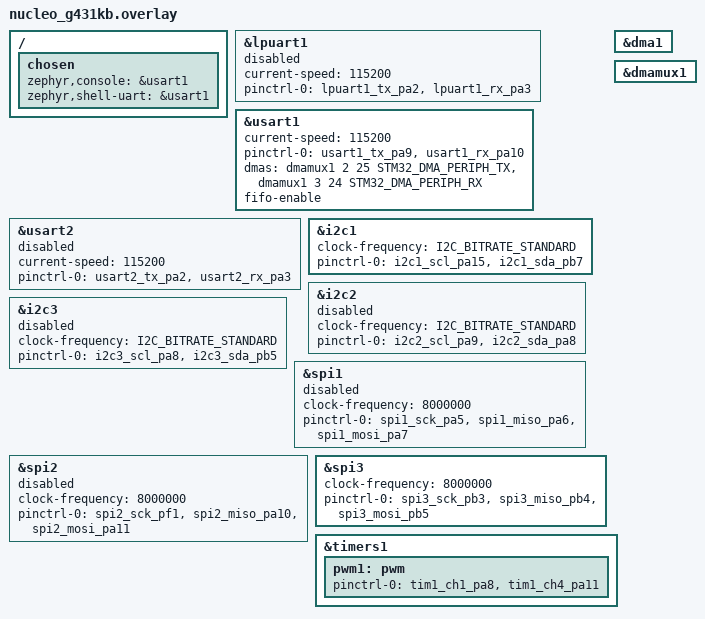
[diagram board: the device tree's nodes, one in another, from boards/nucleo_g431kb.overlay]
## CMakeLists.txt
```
# Copyright (c) 2024 Takayuki Goto <tkg.develop@gmail.com>
# SPDX-License-Identifier: Apache-2.0

cmake_minimum_required(VERSION 3.13.1)

list(APPEND DTS_ROOT ${CMAKE_CURRENT_SOURCE_DIR})

## Switch by Target
if (BOARD STREQUAL "bbc_microbit")
  set(CONF_FILE ${CMAKE_CURRENT_SOURCE_DIR}/boards/bbc/microbit/prj.conf)
elseif (BOARD STREQUAL "bbc_microbit_v2")
  set(CONF_FILE ${CMAKE_CURRENT_SOURCE_DIR}/boards/bbc/microbit_v2/prj.conf)
elseif (BOARD STREQUAL "nucleo_g431kb")
  set(CONF_FILE ${CMAKE_CURRENT_SOURCE_DIR}/boards/st/nucleo_g431kb/prj.conf)
elseif (BOARD STREQUAL "nucleo_f030r8")
  set(CONF_FILE ${CMAKE_CURRENT_SOURCE_DIR}/boards/st/nucleo_f030r8/prj.conf)
elseif (BOARD STREQUAL "nucleo_f401re")
  set(CONF_FILE ${CMAKE_CURRENT_SOURCE_DIR}/boards/st/nucleo_f401re/prj.conf)
elseif (BOARD STREQUAL "nucleo_l552ze_q")
  set(CONF_FILE ${CMAKE_CURRENT_SOURCE_DIR}/boards/st/nucleo_l552ze_q/prj.conf)
elseif (BOARD MATCHES "^stm32h747i_disco")
  set(CONF_FILE ${CMAKE_CURRENT_SOURCE_DIR}/boards/st/stm32h747i_disco/prj.conf)
elseif (BOARD STREQUAL "rpi_pico")
  set(CONF_FILE ${CMAKE_CURRENT_SOURCE_DIR}/boards/raspberrypi/rpi_pico/prj.conf)
elseif (BOARD MATCHES "^rpi_pico2")
  set(CONF_FILE ${CMAKE_CURRENT_SOURCE_DIR}/boards/raspberrypi/rpi_pico2/prj.conf)
elseif (BOARD STREQUAL "arduino_uno_q")
  set(CONF_FILE ${CMAKE_CURRENT_SOURCE_DIR}/boards/arduino/uno_q/prj.conf)
else()
  set(CONF_FILE ${CMAKE_CURRENT_SOURCE_DIR}/boards/generic/prj.conf)
endif()

## Main Process
find_package(Zephyr REQUIRED HINTS $ENV{ZEPHYR_BASE})

project(ZephyrPlaybook)

include_directories(app
PRIVATE
    ${CMAKE_CURRENT_SOURCE_DIR}/include
)

add_subdirectory(${CMAKE_CURRENT_LIST_DIR}/boards)
add_subdirectory(${CMAKE_CURRENT_LIST_DIR}/core)
add_subdirectory(${CMAKE_CURRENT_LIST_DIR}/drivers)
add_subdirectory(${CMAKE_CURRENT_LIST_DIR}/modules)
add_subdirectory(${CMAKE_CURRENT_LIST_DIR}/utils)

zephyr_compile_options(-Werror -Wno-address-of-packed-member)
#zephyr_compile_options(-Wno-address-of-packed-member)
```

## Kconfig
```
# Copyright (c) 2024 Takayuki Goto <tkg.develop@gmail.com>
# SPDX-License-Identifier: Apache-2.0

mainmenu "Zephyr RTOS Playbook configuration"

rsource "drivers/Kconfig"

source "Kconfig.zephyr"
```

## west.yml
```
manifest:
  defaults:
    remote: upstream

  remotes:
    - name: upstream
      url-base: https://github.com/zephyrproject-rtos

  projects:
    - name: zephyr_public
      repo-path: zephyr.git
      path: zephyr
      remote: upstream
      revision: v4.4.0
      clone-depth: 1
      west-commands: scripts/west-commands.yml
      import:
        name-allowlist:
          - cmsis
          - cmsis_6
          - hal_nordic
```

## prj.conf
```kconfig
# Copyright (c) 2024 Takayuki Goto <tkg.develop@gmail.com>
# SPDX-License-Identifier: Apache-2.0

CONFIG_MAIN_STACK_SIZE=4096

## Language
# CONFIG_CPP=y
# CONFIG_REQUIRES_FULL_LIBCPP=y

## Optimizations
CONFIG_SIZE_OPTIMIZATIONS=y
# CONFIG_SIZE_OPTIMIZATIONS_AGGRESSIVE=y
# CONFIG_SPEED_OPTIMIZATIONS=y
# CONFIG_DEBUG_OPTIMIZATIONS=y
# CONFIG_NO_OPTIMIZATIONS=y

CONFIG_LVGL=y
CONFIG_LV_Z_MEM_POOL_SIZE=16384

CONFIG_DISPLAY=y
```

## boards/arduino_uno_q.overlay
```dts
/*
 * Copyright (c) 2026 Takayuki Goto <tkg.develop@gmail.com>
 *
 * SPDX-License-Identifier: Apache-2.0
 */

/ {
};
```

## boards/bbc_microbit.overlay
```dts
/*
 * Copyright (c) 2024 Takayuki Goto <tkg.develop@gmail.com>
 *
 * SPDX-License-Identifier: Apache-2.0
 */

/ {
	zephyr,user {
		/* period cell corresponds to initial period */
		pwms = <&sw_pwm 0 PWM_USEC(1500) PWM_POLARITY_NORMAL>;
	};
};

&sw_pwm {
	status = "okay";
	channel-gpios = <&edge_connector 0 GPIO_ACTIVE_HIGH>;
};

&lsm303agr_magn {
    status = "okay";
};

&mma8653fc {
    status = "okay";
};

&lsm303agr_accel {
    status = "okay";
};
```

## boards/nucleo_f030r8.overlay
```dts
/*
 * Copyright (c) 2024 Takayuki Goto <tkg.develop@gmail.com>
 *
 * SPDX-License-Identifier: Apache-2.0
 */

/ {
};

&usart1 {
	current-speed = <115200>;
};

&i2c1 {
	clock-frequency = <I2C_BITRATE_STANDARD>;
};
```

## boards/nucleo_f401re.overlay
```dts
/*
 * Copyright (c) 2024 Takayuki Goto <tkg.develop@gmail.com>
 *
 * SPDX-License-Identifier: Apache-2.0
 */

/ {
};

&usart1 {
	current-speed = <115200>;
};
```

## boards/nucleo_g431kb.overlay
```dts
/*
 * Copyright (c) 2025 Takayuki Goto <tkg.develop@gmail.com>
 *
 * SPDX-License-Identifier: Apache-2.0
 */

/ {
	chosen {
		zephyr,console = &usart1;
		zephyr,shell-uart = &usart1;
	};
};

&lpuart1 {
    status = "disabled";
    current-speed = <115200>;

    // lpuart1_tx_pa2
    // lpuart1_rx_pa3
    pinctrl-0 = <&lpuart1_tx_pa2 &lpuart1_rx_pa3>;
    pinctrl-names = "default";

    // LL_DMAMUX_REQ_LPUART1_TX, LL_DMAMUX_REQ_LPUART1_RX
//  dmas = <&dmamux1 0 35 STM32_DMA_PERIPH_TX>,
//         <&dmamux1 1 34 STM32_DMA_PERIPH_RX>;
//  dma-names = "tx", "rx";
// fifo-enable;
};

&usart1 {
    status = "okay";
    current-speed = <115200>;

    // usart1_tx_pa9, usart1_tx_pb6
    // usart1_rx_pa10, usart1_rx_pb7
    pinctrl-0 = <&usart1_tx_pa9 &usart1_rx_pa10>;
    pinctrl-names = "default";

	// LL_DMAMUX_REQ_USART1_TX, LL_DMAMUX_REQ_USART1_RX
	dmas = <&dmamux1 2 25 STM32_DMA_PERIPH_TX>,
	       <&dmamux1 3 24 STM32_DMA_PERIPH_RX>;
	dma-names = "tx", "rx";
	fifo-enable;
};

&usart2 {
    status = "disabled";
    current-speed = <115200>;

    // usart2_tx_pa2, usart2_tx_pa14, usart2_tx_pb3
    // usart2_rx_pa3, usart2_rx_pa15, usart2_rx_pb4
    pinctrl-0 = < &usart2_tx_pa2 &usart2_rx_pa3 >;
    pinctrl-names = "default";

	// LL_DMAMUX_REQ_USART2_TX, LL_DMAMUX_REQ_USART2_RX
//  dmas = <&dmamux1 4 27 STM32_DMA_PERIPH_TX>,
//         <&dmamux1 5 26 STM32_DMA_PERIPH_RX>;
//  dma-names = "tx", "rx";
};

&i2c1 {
    status = "okay";
    clock-frequency = <I2C_BITRATE_STANDARD>;

    // i2c1_scl_pa13, i2c1_scl_pa15, i2c1_scl_pb8
    // i2c1_sda_pa14, i2c1_sda_pb7
    pinctrl-0 = < &i2c1_scl_pa15 &i2c1_sda_pb7 >;
    pinctrl-names = "default";
};

&i2c2 {
    status = "disabled";
    clock-frequency = <I2C_BITRATE_STANDARD>;

    // i2c2_scl_pa9
    // i2c2_sda_pa8, i2c2_sda_pf0
    pinctrl-0 = < &i2c2_scl_pa9 &i2c2_sda_pa8 >;
    pinctrl-names = "default";
};

&i2c3 {
    status = "disabled";
    clock-frequency = <I2C_BITRATE_STANDARD>;

    // i2c3_scl_pa8
    // i2c3_sda_pb5
    pinctrl-0 = < &i2c3_scl_pa8 &i2c3_sda_pb5 >;
    pinctrl-names = "default";
};

&spi1 {
    status = "disabled";
    clock-frequency = <8000000>;

    // spi1_sck_pa5, spi1_sck_pb3
    // spi1_miso_pa6, spi1_miso_pb4
    // spi1_mosi_pa7, spi1_mosi_pb5
    pinctrl-0 = <&spi1_sck_pa5 &spi1_miso_pa6 &spi1_mosi_pa7>;
    pinctrl-names = "default";
//  cs-gpios = <&gpiob 7 GPIO_ACTIVE_LOW>;
};

&spi2 {
    status = "disabled";
    clock-frequency = <8000000>;

    // spi2_sck_pf1
    // spi2_miso_pa10
    // spi2_mosi_pa11
    pinctrl-0 = <&spi2_sck_pf1 &spi2_miso_pa10 &spi2_mosi_pa11>;
    pinctrl-names = "default";
//  cs-gpios = <&gpioa 1 GPIO_ACTIVE_LOW>;
};

&spi3 {
    status = "okay";
    clock-frequency = <8000000>;

    // spi3_sck_pb3
    // spi3_miso_pb4
    // spi3_mosi_pb5
    pinctrl-0 = <&spi3_sck_pb3 &spi3_miso_pb4 &spi3_mosi_pb5>;
    pinctrl-names = "default";
//  cs-gpios = <&gpiob 7 GPIO_ACTIVE_LOW>;
};

&dma1 {
	status = "okay";
};

&dmamux1 {
	status = "okay";
};

&timers1 {
    status = "okay";
    pwm1: pwm {
        status = "okay";

        // tim1_ch1_pa8, tim1_ch1n_pa7, tim1_ch1n_pa11
        // tim1_ch2_pa9, tim1_ch2n_pa12, tim1_ch2n_pb0
        // tim1_ch3_pa10, tim1_ch3n_pf0
        // tim1_ch4_pa11,
        pinctrl-0 = <&tim1_ch1_pa8 &tim1_ch4_pa11>;
        pinctrl-names = "default";
    };
};
/*
&timers2 {
    status = "disabled";
    pwm2: pwm {
        status = "disabled";

        // tim2_ch1_pa0, tim2_ch2_pa1, tim2_ch3_pa2, tim2_ch4_pa3
        // tim2_ch1_pa5, tim2_ch3_pa9, tim2_ch4_pa10, tim2_ch1_pa15
        // tim2_ch2_pb3
//      pinctrl-0 = <&>;
        pinctrl-names = "default";
    };
};

&timers3 {
    status = "disabled";
    pwm3: pwm {
        status = "disabled";

        // tim3_ch2_pa4, tim3_ch1_pa6, tim3_ch2_pa7, tim3_ch3_pb0
        // tim3_ch1_pb4, tim3_ch2_pb5, tim3_ch4_pb7
//      pinctrl-0 = <&>;
        pinctrl-names = "default";
    };
};

&timers4 {
    status = "disabled";
    pwm4: pwm {
        status = "disabled";

        // tim4_ch1_pa11, tim4_ch2_pa12, tim4_ch3_pa13, tim4_ch1_pb6
        // tim4_ch2_pb7, tim4_ch3_pb8
//      pinctrl-0 = <&>;
        pinctrl-names = "default";
    };
};

&timers8 {
    status = "disabled";
    pwm8: pwm {
        status = "disabled";

        // tim8_ch1n_pa7, tim8_ch2_pa14, tim8_ch1_pa15, tim8_ch2n_pb0
        // tim8_ch1n_pb3, tim8_ch2n_pb4, tim8_ch3n_pb5, tim8_ch1_pb6
        // tim8_ch2_pb8
//      pinctrl-0 = <&>;
        pinctrl-names = "default";
    };
};

&timers15 {
    status = "disabled";
    pwm15: pwm {
        status = "disabled";

        // tim15_ch1n_pa1, tim15_ch1_pa2, tim15_ch2_pa3
//      pinctrl-0 = <&>;
        pinctrl-names = "default";
    };
};

&timers16 {
    status = "disabled";
    pwm16: pwm {
        status = "disabled";

        // tim16_ch1_pa6, tim16_ch1_pa12, tim16_ch1n_pa13, tim16_ch1_pb4
        // tim16_ch1n_pb6, tim16_ch1_pb8
//      pinctrl-0 = <&>;
        pinctrl-names = "default";
    };
};

&timers17 {
    status = "disabled";
    pwm17: pwm {
        status = "disabled";

        // tim17_ch1_pa7, tim17_ch1_pb5, tim17_ch1n_pb7
//      pinctrl-0 = <&>;
        pinctrl-names = "default";
    };
};
*/
```

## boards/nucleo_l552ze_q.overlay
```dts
/*
 * Copyright (c) 2024 Takayuki Goto <tkg.develop@gmail.com>
 *
 * SPDX-License-Identifier: Apache-2.0
 */

/ {
};

&usart1 {
	pinctrl-0 = <&usart1_tx_pb6 &usart1_rx_pb7>;
    pinctrl-names = "default";
	current-speed = <115200>;
    status = "okay";
};
```

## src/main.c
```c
/*
 * Copyright (c) 2024 Takayuki Goto <tkg.develop@gmail.com>
 *
 * SPDX-License-Identifier: Apache-2.0
 */

#include <zephyr/kernel.h>
#include <zephyr/drivers/display.h>
#include <lvgl.h>
#include "boards/unique.h"

extern const lv_image_dsc_t g_img_osc_tokyo;

int main(void)
{
	lv_obj_t *img;

	img = lv_image_create(lv_screen_active());
	lv_image_set_src(img, &g_img_osc_tokyo);
	lv_obj_center(img);

	while (true) {
		k_msleep(MIN(lv_timer_handler(), INT32_MAX));
	}

	return 0;
}
```
